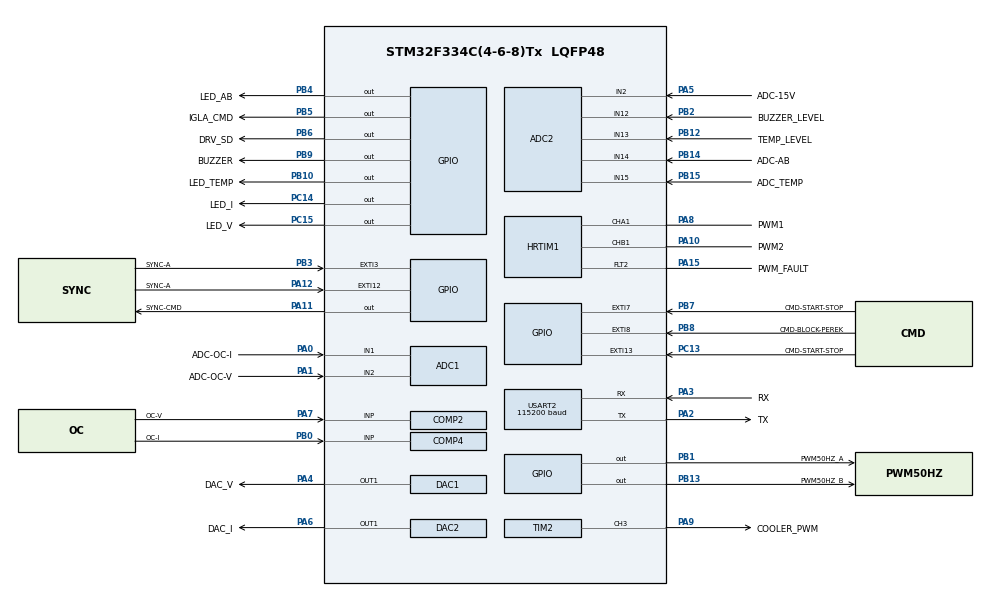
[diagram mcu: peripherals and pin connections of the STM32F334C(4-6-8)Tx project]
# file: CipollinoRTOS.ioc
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ADC1.ContinuousConvMode=ENABLE
ADC1.DMAContinuousRequests=ENABLE
ADC1.EnableRegularConversion=DISABLE
ADC1.ExternalTrigInjecConv=ADC_EXTERNALTRIGINJECCONV_HRTIM_TRG2
ADC1.ExternalTrigInjecConvEdge=ADC_EXTERNALTRIGINJECCONV_EDGE_RISINGFALLING
ADC1.InjNumberOfConversion=2
ADC1.InjectedChannel-1\#ChannelInjectedConversion=ADC_CHANNEL_1
ADC1.InjectedChannel-2\#ChannelInjectedConversion=ADC_CHANNEL_1
ADC1.InjectedConvMode=Discontinuous
ADC1.InjectedOffset-1\#ChannelInjectedConversion=0
ADC1.InjectedOffset-2\#ChannelInjectedConversion=0
ADC1.InjectedOffsetNumber-1\#ChannelInjectedConversion=ADC_OFFSET_NONE
ADC1.InjectedOffsetNumber-2\#ChannelInjectedConversion=ADC_OFFSET_NONE
ADC1.InjectedRank-1\#ChannelInjectedConversion=1
ADC1.InjectedRank-2\#ChannelInjectedConversion=2
ADC1.InjectedSamplingTime-1\#ChannelInjectedConversion=ADC_SAMPLETIME_7CYCLES_5
ADC1.InjectedSamplingTime-2\#ChannelInjectedConversion=ADC_SAMPLETIME_7CYCLES_5
ADC1.QueueInjectedContext=ENABLE
ADC1.SubFamily=STM32F334x8
ADC1.master=1
ADC2.AWD1HighThreshold=2500
ADC2.AWD1ITMode=DISABLE
ADC2.AWD1LowThreshold=1000
ADC2.Channel-0\#ChannelRegularConversion=ADC_CHANNEL_2
ADC2.Channel-2\#ChannelRegularConversion=ADC_CHANNEL_2
ADC2.Channel-3\#ChannelRegularConversion=ADC_CHANNEL_2
ADC2.Channel-4\#ChannelRegularConversion=ADC_CHANNEL_2
ADC2.Channel-5\#ChannelRegularConversion=ADC_CHANNEL_2
ADC2.ContinuousConvMode=ENABLE
ADC2.DMAContinuousRequests=ENABLE
ADC2.EOCSelection=ADC_EOC_SEQ_CONV
ADC2.EnableAnalogWatchDog1=true
ADC2.EnableAnalogWatchDog2=false
ADC2.EnableAnalogWatchDog3=false
ADC2.EnableInjectedConversion=DISABLE
ADC2.NbrOfConversion=5
ADC2.NbrOfConversionFlag=1
ADC2.Offset-0\#ChannelRegularConversion=0
ADC2.Offset-2\#ChannelRegularConversion=0
ADC2.Offset-3\#ChannelRegularConversion=0
ADC2.Offset-4\#ChannelRegularConversion=0
ADC2.Offset-5\#ChannelRegularConversion=0
ADC2.OffsetNumber-0\#ChannelRegularConversion=ADC_OFFSET_NONE
ADC2.OffsetNumber-2\#ChannelRegularConversion=ADC_OFFSET_NONE
ADC2.OffsetNumber-3\#ChannelRegularConversion=ADC_OFFSET_NONE
ADC2.OffsetNumber-4\#ChannelRegularConversion=ADC_OFFSET_NONE
ADC2.OffsetNumber-5\#ChannelRegularConversion=ADC_OFFSET_NONE
ADC2.Rank-0\#ChannelRegularConversion=1
ADC2.Rank-2\#ChannelRegularConversion=2
ADC2.Rank-3\#ChannelRegularConversion=3
ADC2.Rank-4\#ChannelRegularConversion=4
ADC2.Rank-5\#ChannelRegularConversion=5
ADC2.SamplingTime-0\#ChannelRegularConversion=ADC_SAMPLETIME_601CYCLES_5
ADC2.SamplingTime-2\#ChannelRegularConversion=ADC_SAMPLETIME_601CYCLES_5
ADC2.SamplingTime-3\#ChannelRegularConversion=ADC_SAMPLETIME_601CYCLES_5
ADC2.SamplingTime-4\#ChannelRegularConversion=ADC_SAMPLETIME_601CYCLES_5
ADC2.SamplingTime-5\#ChannelRegularConversion=ADC_SAMPLETIME_601CYCLES_5
ADC2.SubFamily=STM32F334x8
ADC2.WatchdogChannel=ADC_CHANNEL_2
COMP2.InvertingInput=COMP_INVERTINGINPUT_DAC1_CH1
COMP2.TriggerMode=COMP_TRIGGERMODE_IT_RISING_FALLING
COMP4.InvertingInput=COMP_INVERTINGINPUT_DAC2_CH1
COMP4.TriggerMode=COMP_TRIGGERMODE_IT_RISING_FALLING
Dma.ADC2.1.Direction=DMA_PERIPH_TO_MEMORY
Dma.ADC2.1.Instance=DMA1_Channel2
Dma.ADC2.1.MemDataAlignment=DMA_MDATAALIGN_HALFWORD
Dma.ADC2.1.MemInc=DMA_MINC_ENABLE
Dma.ADC2.1.Mode=DMA_CIRCULAR
Dma.ADC2.1.PeriphDataAlignment=DMA_PDATAALIGN_HALFWORD
Dma.ADC2.1.PeriphInc=DMA_PINC_DISABLE
Dma.ADC2.1.Priority=DMA_PRIORITY_MEDIUM
Dma.Request0=USART2_TX
Dma.Request1=ADC2
Dma.USART2_TX.0.Direction=DMA_MEMORY_TO_PERIPH
Dma.USART2_TX.0.Instance=DMA1_Channel7
Dma.USART2_TX.0.MemDataAlignment=DMA_MDATAALIGN_BYTE
Dma.USART2_TX.0.MemInc=DMA_MINC_ENABLE
Dma.USART2_TX.0.Mode=DMA_CIRCULAR
Dma.USART2_TX.0.PeriphDataAlignment=DMA_PDATAALIGN_BYTE
Dma.USART2_TX.0.PeriphInc=DMA_PINC_DISABLE
Dma.USART2_TX.0.Priority=DMA_PRIORITY_LOW
HRTIM1.ADCTrigger1_Source1=HRTIM_ADCTRIGGEREVENT13_MASTER_CMP1
HRTIM1.ADCTrigger1_Source2=HRTIM_ADCTRIGGEREVENT13_MASTER_CMP2
HRTIM1.ADCTrigger1_Source3=HRTIM_ADCTRIGGEREVENT13_MASTER_CMP3
HRTIM1.ADCTrigger1_Source4=HRTIM_ADCTRIGGEREVENT13_MASTER_CMP4
HRTIM1.ADCTrigger2_Source1=HRTIM_ADCTRIGGEREVENT24_MASTER_CMP1
HRTIM1.ADCTrigger2_Source2=HRTIM_ADCTRIGGEREVENT24_MASTER_CMP3
HRTIM1.ADCTrigger2_Source3=HRTIM_ADCTRIGGEREVENT24_TIMERA_CMP2
HRTIM1.ADCTrigger2_Source4=HRTIM_ADCTRIGGEREVENT24_TIMERA_CMP3
HRTIM1.ADCTrigger2_Source5=HRTIM_ADCTRIGGEREVENT24_TIMERA_CMP4
HRTIM1.ADCTrigger2_Source6=HRTIM_ADCTRIGGEREVENT24_TIMERB_CMP2
HRTIM1.ADCTrigger2_Source7=HRTIM_ADCTRIGGEREVENT24_TIMERB_CMP3
HRTIM1.ADCTrigger2_Source8=HRTIM_ADCTRIGGEREVENT24_TIMERB_CMP4
HRTIM1.ADCTrigger3_Source1=HRTIM_ADCTRIGGEREVENT13_TIMERB_CMP2
HRTIM1.ADCTrigger3_Source2=HRTIM_ADCTRIGGEREVENT13_TIMERB_CMP3
HRTIM1.ADCTrigger3_Source3=HRTIM_ADCTRIGGEREVENT13_TIMERB_CMP4
HRTIM1.ADCTrigger4_Source1=HRTIM_ADCTRIGGEREVENT24_MASTER_PERIOD
HRTIM1.ADCTrigger_Id1=__NULL
HRTIM1.ADCTrigger_Id2=HRTIM_ADCTRIGGER_2
HRTIM1.ADCTrigger_Id3=__NULL
HRTIM1.ADCTrigger_Id4=__NULL
HRTIM1.CaptureUnit1-Output_TA1=HRTIM_CAPTUREUNIT_1
HRTIM1.CaptureUnit1-Output_TB1=HRTIM_CAPTUREUNIT_1
HRTIM1.CaptureUnit2-Output_TA1=HRTIM_CAPTUREUNIT_2
HRTIM1.CaptureUnit2-Output_TB1=HRTIM_CAPTUREUNIT_2
HRTIM1.CompareUnit1-MasterTimer=HRTIM_COMPAREUNIT_1
HRTIM1.CompareUnit1-Output_TA1=HRTIM_COMPAREUNIT_1
HRTIM1.CompareUnit1-Output_TB1=HRTIM_COMPAREUNIT_1
HRTIM1.CompareUnit2-MasterTimer=HRTIM_COMPAREUNIT_2
HRTIM1.CompareUnit2-Output_TA1=HRTIM_COMPAREUNIT_2
HRTIM1.CompareUnit2-Output_TB1=HRTIM_COMPAREUNIT_2
HRTIM1.CompareUnit3-MasterTimer=HRTIM_COMPAREUNIT_3
HRTIM1.CompareUnit3-Output_TA1=HRTIM_COMPAREUNIT_3
HRTIM1.CompareUnit3-Output_TB1=HRTIM_COMPAREUNIT_3
HRTIM1.CompareUnit4-MasterTimer=HRTIM_COMPAREUNIT_4
HRTIM1.CompareUnit4-Output_TA1=HRTIM_COMPAREUNIT_4
HRTIM1.CompareUnit4-Output_TB1=HRTIM_COMPAREUNIT_4
HRTIM1.CompareValue1-MasterTimer=2300
HRTIM1.CompareValue1-Output_TA1=7000
HRTIM1.CompareValue1-Output_TB1=40000
HRTIM1.CompareValue2-MasterTimer=30459
HRTIM1.CompareValue2-Output_TA1=14000
HRTIM1.CompareValue2-Output_TB1=47000
HRTIM1.CompareValue3-MasterTimer=35059
HRTIM1.CompareValue3-Output_TA1=21000
HRTIM1.CompareValue3-Output_TB1=54000
HRTIM1.CompareValue4-MasterTimer=63219
HRTIM1.CompareValue4-Output_TA1=28000
HRTIM1.CompareValue4-Output_TB1=61000
HRTIM1.EnableCalibration=DLLSimpleCalibration
HRTIM1.Event4-Output_TA1=__NULL
HRTIM1.Event_EEV1=HRTIM_EVENT_1
HRTIM1.Event_EEV2=HRTIM_EVENT_2
HRTIM1.Event_EEV3=__NULL
HRTIM1.Event_EEV4=HRTIM_EVENT_4
HRTIM1.FastMode_EEV1=HRTIM_EVENTFASTMODE_ENABLE
HRTIM1.FastMode_EEV2=HRTIM_EVENTFASTMODE_ENABLE
HRTIM1.FastMode_EEV4=HRTIM_EVENTFASTMODE_ENABLE
HRTIM1.FaultEnable_Source1-Output_TA1=HRTIM_TIMFAULTENABLE_FAULT2
HRTIM1.FaultEnable_Source1-Output_TB1=HRTIM_TIMFAULTENABLE_FAULT2
HRTIM1.FaultLevel1-Output_TA1=HRTIM_OUTPUTFAULTLEVEL_INACTIVE
HRTIM1.FaultLevel1-Output_TB1=HRTIM_OUTPUTFAULTLEVEL_INACTIVE
HRTIM1.Filter_FaultLine2=HRTIM_FAULTFILTER_15
HRTIM1.HRTIMInterruptResquests1=HRTIM_IT_FLT2
HRTIM1.HRTIMInterruptResquests2=HRTIM_IT_SYSFLT
HRTIM1.InterruptRequests1-Output_TA1=HRTIM_TIM_IT_CMP1
HRTIM1.InterruptRequests1-Output_TB1=HRTIM_TIM_IT_CMP1
HRTIM1.InterruptRequests1_Master=HRTIM_MASTER_IT_MREP
HRTIM1.InterruptRequests2-Output_TA1=HRTIM_TIM_IT_CMP2
HRTIM1.InterruptRequests2-Output_TB1=HRTIM_TIM_IT_CMP2
HRTIM1.InterruptRequests2_Master=HRTIM_MASTER_IT_MCMP1
HRTIM1.InterruptRequests3-Output_TA1=HRTIM_TIM_IT_CMP3
HRTIM1.InterruptRequests3-Output_TB1=HRTIM_TIM_IT_CMP3
HRTIM1.InterruptRequests3_Master=HRTIM_MASTER_IT_MCMP2
HRTIM1.InterruptRequests4-Output_TA1=HRTIM_TIM_IT_CMP4
HRTIM1.InterruptRequests4-Output_TB1=HRTIM_TIM_IT_CMP4
HRTIM1.InterruptRequests4_Master=HRTIM_MASTER_IT_MCMP3
HRTIM1.InterruptRequests5-Output_TA1=HRTIM_TIM_IT_CPT1
HRTIM1.InterruptRequests5-Output_TB1=HRTIM_TIM_IT_CPT1
HRTIM1.InterruptRequests5_Master=HRTIM_MASTER_IT_MCMP4
HRTIM1.InterruptRequests6-Output_TA1=HRTIM_TIM_IT_CPT2
HRTIM1.InterruptRequests6-Output_TB1=HRTIM_TIM_IT_CPT2
HRTIM1.ModeTimeBase-Output_TA1=HRTIM_MODE_SINGLESHOT_RETRIGGERABLE
HRTIM1.ModeTimeBase-Output_TB1=HRTIM_MODE_SINGLESHOT_RETRIGGERABLE
HRTIM1.NumberADCTriggerSource1=4
HRTIM1.NumberADCTriggerSource2=8
HRTIM1.NumberADCTriggerSource3=3
HRTIM1.NumberADCTriggerSource4=1
HRTIM1.NumberDMARequests_Master=0
HRTIM1.NumberFaultEnable-Output_TA1=1
HRTIM1.NumberFaultEnable-Output_TB1=1
HRTIM1.NumberInterruptRequests-Output_TA1=6
HRTIM1.NumberInterruptRequests-Output_TB1=6
HRTIM1.NumberInterruptRequests_Master-MasterTimer=5
HRTIM1.NumberResetSource1-Output_TA1=4
HRTIM1.NumberResetSource1-Output_TB1=4
HRTIM1.NumberResetTrigger-Output_TA1=4
HRTIM1.NumberResetTrigger-Output_TB1=4
HRTIM1.NumberSetSource1-Output_TA1=1
HRTIM1.NumberSetSource1-Output_TB1=1
HRTIM1.NumberTriggerSource_Captureconfig1-Output_TA1=2
HRTIM1.NumberTriggerSource_Captureconfig1-Output_TB1=2
HRTIM1.NumberTriggerSource_Captureconfig2-Output_TA1=1
HRTIM1.NumberTriggerSource_Captureconfig2-Output_TB1=1
HRTIM1.NumberUpdateTrigger-Output_TA1=1
HRTIM1.NumberUpdateTrigger-Output_TB1=1
HRTIM1.ORingUpdateSource_ADCTrigger1=HRTIM_ADCTRIGGERUPDATE_MASTER
HRTIM1.ORingUpdateSource_ADCTrigger2=HRTIM_ADCTRIGGERUPDATE_MASTER
HRTIM1.ORingUpdateSource_ADCTrigger3=HRTIM_ADCTRIGGERUPDATE_TIMER_B
HRTIM1.Periode_MASTER=65503
HRTIM1.PrescalerRatio_MASTER=HRTIM_PRESCALERRATIO_MUL16
HRTIM1.PrescalerRatio_TA=HRTIM_PRESCALERRATIO_MUL16
HRTIM1.PrescalerRatio_TB=HRTIM_PRESCALERRATIO_MUL16
HRTIM1.ResetOutput1_Source1-Output_TA1=HRTIM_OUTPUTRESET_MASTERCMP2
HRTIM1.ResetOutput1_Source1-Output_TB1=HRTIM_OUTPUTRESET_MASTERCMP4
HRTIM1.ResetOutput1_Source2-Output_TA1=HRTIM_OUTPUTRESET_EEV_1
HRTIM1.ResetOutput1_Source2-Output_TB1=HRTIM_OUTPUTRESET_EEV_1
HRTIM1.ResetOutput1_Source3-Output_TA1=HRTIM_OUTPUTRESET_EEV_2
HRTIM1.ResetOutput1_Source3-Output_TB1=HRTIM_OUTPUTRESET_EEV_2
HRTIM1.ResetOutput1_Source4-Output_TA1=HRTIM_OUTPUTRESET_EEV_4
HRTIM1.ResetOutput1_Source4-Output_TB1=HRTIM_OUTPUTRESET_EEV_4
HRTIM1.ResetTrigger1-Output_TA1=HRTIM_TIMRESETTRIGGER_MASTER_CMP2
HRTIM1.ResetTrigger1-Output_TB1=HRTIM_TIMRESETTRIGGER_MASTER_CMP4
HRTIM1.ResetTrigger2-Output_TA1=HRTIM_TIMRESETTRIGGER_EEV_1
HRTIM1.ResetTrigger2-Output_TB1=HRTIM_TIMRESETTRIGGER_EEV_1
HRTIM1.ResetTrigger3-Output_TA1=HRTIM_TIMRESETTRIGGER_EEV_2
HRTIM1.ResetTrigger3-Output_TB1=HRTIM_TIMRESETTRIGGER_EEV_2
HRTIM1.ResetTrigger4-Output_TA1=HRTIM_TIMRESETTRIGGER_EEV_4
HRTIM1.ResetTrigger4-Output_TB1=HRTIM_TIMRESETTRIGGER_EEV_4
HRTIM1.Sensitivity_EEV1=HRTIM_EVENTSENSITIVITY_LEVEL
HRTIM1.SetOutput1_Source1-Output_TA1=HRTIM_OUTPUTSET_MASTERCMP1
HRTIM1.SetOutput1_Source1-Output_TB1=HRTIM_OUTPUTSET_MASTERCMP3
HRTIM1.Source_EEV4=HRTIM_EVENTSRC_4
HRTIM1.TriggerCapture1_Source1-Output_TA1=HRTIM_CAPTURETRIGGER_EEV_1
HRTIM1.TriggerCapture1_Source1-Output_TB1=HRTIM_CAPTURETRIGGER_EEV_1
HRTIM1.TriggerCapture1_Source2-Output_TA1=HRTIM_CAPTURETRIGGER_EEV_2
HRTIM1.TriggerCapture1_Source2-Output_TB1=HRTIM_CAPTURETRIGGER_EEV_2
HRTIM1.TriggerCapture2_Source1-Output_TA1=HRTIM_CAPTURETRIGGER_TA1_RESET
HRTIM1.TriggerCapture2_Source1-Output_TB1=HRTIM_CAPTURETRIGGER_TB1_SET
HRTIM1.UpdateTrigger1-Output_TA1=HRTIM_TIMUPDATETRIGGER_MASTER
HRTIM1.UpdateTrigger1-Output_TB1=HRTIM_TIMUPDATETRIGGER_MASTER
IWDG.Prescaler=IWDG_PRESCALER_128
Mcu.Family=STM32F3
Mcu.Name=STM32F334C(4-6-8)Tx
Mcu.Package=LQFP48
NVIC.COMP2_IRQn=true\:0\:0\:false\:false\:true\:false\:true
NVIC.COMP4_6_IRQn=true\:0\:0\:false\:false\:true\:false\:true
NVIC.DMA1_Channel2_IRQn=true\:0\:0\:false\:false\:true\:false\:true
NVIC.DMA1_Channel7_IRQn=true\:0\:0\:false\:false\:true\:false\:true
NVIC.EXTI15_10_IRQn=true\:0\:2\:false\:false\:true\:true\:true
NVIC.EXTI3_IRQn=true\:0\:2\:false\:false\:true\:true\:true
NVIC.EXTI9_5_IRQn=true\:0\:2\:false\:false\:true\:true\:true
NVIC.HRTIM1_FLT_IRQn=true\:0\:0\:false\:false\:true\:true\:true
NVIC.HRTIM1_Master_IRQn=true\:0\:0\:false\:false\:true\:true\:true
NVIC.HRTIM1_TIMA_IRQn=true\:0\:0\:false\:false\:true\:true\:true
NVIC.HRTIM1_TIMB_IRQn=true\:0\:0\:false\:false\:true\:true\:true
NVIC.PVD_IRQn=true\:0\:2\:true\:false\:true\:true\:true
NVIC.PriorityGroup=NVIC_PRIORITYGROUP_1
PA0.GPIO_Label=ADC-OC-I
PA0.Mode=IN1-Single-Ended
PA0.Signal=ADC1_IN1
PA1.GPIO_Label=ADC-OC-V
PA1.Mode=IN2-Single-Ended
PA1.Signal=ADC1_IN2
PA10.GPIO_Label=PWM2
PA10.Mode=Output_TB1
PA10.Signal=HRTIM1_CHB1
PA11.GPIO_Label=SYNC-CMD
PA11.GPIO_Speed=GPIO_SPEED_FREQ_HIGH
PA11.Signal=GPIO_Output
PA12.GPIO_Label=SYNC-A
PA12.GPIO_ModeDefaultEXTI=GPIO_MODE_IT_RISING_FALLING
PA12.Signal=GPXTI12
PA13.GPIO_Label=DIO
PA13.Mode=Serial_Wire
PA13.Signal=SYS_JTMS-SWDIO
PA14.GPIO_Label=CLK
PA14.Mode=Serial_Wire
PA14.Signal=SYS_JTCK-SWCLK
PA15.GPIO_Label=PWM_FAULT
PA15.Mode=Fault_Enable2
PA15.Signal=HRTIM1_FLT2
PA2.GPIO_Label=TX
PA2.Mode=Asynchronous
PA2.Signal=USART2_TX
PA3.GPIO_Label=RX
PA3.Mode=Asynchronous
PA3.Signal=USART2_RX
PA4.GPIO_Label=DAC_V
PA4.Signal=COMP_DAC11_group
PA5.GPIO_Label=ADC-15V
PA5.Mode=IN2-Single-Ended
PA5.Signal=ADC2_IN2
PA6.GPIO_Label=DAC_I
PA6.Signal=COMP_DAC21_group
PA7.GPIO_Label=OC-V
PA7.Mode=INP
PA7.Signal=COMP2_INP
PA8.GPIO_Label=PWM1
PA8.Mode=Output_TA1
PA8.Signal=HRTIM1_CHA1
PA9.GPIO_Label=COOLER_PWM
PA9.GPIO_Speed=GPIO_SPEED_FREQ_HIGH
PA9.Signal=S_TIM2_CH3
PB0.GPIO_Label=OC-I
PB0.Mode=INP
PB0.Signal=COMP4_INP
PB1.GPIO_Label=PWM50HZ_A
PB1.GPIO_Speed=GPIO_SPEED_FREQ_HIGH
PB1.Signal=GPIO_Output
PB10.GPIO_Label=LED_TEMP
PB10.GPIO_Speed=GPIO_SPEED_FREQ_HIGH
PB10.Signal=GPIO_Output
PB12.GPIO_Label=TEMP_LEVEL
PB12.Mode=IN13-Single-Ended
PB12.Signal=ADC2_IN13
PB13.GPIO_Label=PWM50HZ_B
PB13.GPIO_Speed=GPIO_SPEED_FREQ_HIGH
PB13.Signal=GPIO_Output
PB14.GPIO_Label=ADC-AB
PB14.Mode=IN14-Single-Ended
PB14.Signal=ADC2_IN14
PB15.GPIO_Label=ADC_TEMP
PB15.Mode=IN15-Single-Ended
PB15.Signal=ADC2_IN15
PB2.GPIO_Label=BUZZER_LEVEL
PB2.Mode=IN12-Single-Ended
PB2.Signal=ADC2_IN12
PB3.GPIO_Label=SYNC-A
PB3.GPIO_ModeDefaultEXTI=GPIO_MODE_IT_RISING_FALLING
PB3.Signal=GPXTI3
PB4.GPIO_Label=LED_AB
PB4.GPIO_Speed=GPIO_SPEED_FREQ_HIGH
PB4.Signal=GPIO_Output
PB5.GPIO_Label=IGLA_CMD
PB5.GPIO_Speed=GPIO_SPEED_FREQ_HIGH
PB5.Signal=GPIO_Output
PB6.GPIO_FM6=SYSCFG_CFGR1_I2C_PB6_FMP
PB6.GPIO_Label=DRV_SD
PB6.GPIO_Speed=GPIO_SPEED_FREQ_HIGH
PB6.Signal=GPIO_Output
PB7.GPIO_Label=CMD-START-STOP
PB7.GPIO_ModeDefaultEXTI=GPIO_MODE_IT_RISING_FALLING
PB7.Signal=GPXTI7
PB8.GPIO_Label=CMD-BLOCK-PEREK
PB8.GPIO_ModeDefaultEXTI=GPIO_MODE_IT_RISING_FALLING
PB8.Signal=GPXTI8
PB9.GPIO_FM9=SYSCFG_CFGR1_I2C_PB9_FMP
PB9.GPIO_Label=BUZZER
PB9.GPIO_Speed=GPIO_SPEED_FREQ_HIGH
PB9.Signal=GPIO_Output
PC13.GPIO_Label=CMD-START-STOP
PC13.GPIO_ModeDefaultEXTI=GPIO_MODE_IT_RISING_FALLING
PC13.Signal=GPXTI13
PC14\ /\ OSC32_IN.GPIO_Label=LED_I
PC14\ /\ OSC32_IN.GPIO_Speed=GPIO_SPEED_FREQ_HIGH
PC14\ /\ OSC32_IN.Signal=GPIO_Output
PC15\ /\ OSC32_OUT.GPIO_Label=LED_V
PC15\ /\ OSC32_OUT.GPIO_Speed=GPIO_SPEED_FREQ_HIGH
PC15\ /\ OSC32_OUT.Signal=GPIO_Output
PF0\ /\ OSC_IN.GPIO_Label=OSC_IN
PF0\ /\ OSC_IN.Mode=HSE-External-Oscillator
PF0\ /\ OSC_IN.Signal=RCC_OSC_IN
PF1\ /\ OSC_OUT.GPIO_Label=OSC_OUT
PF1\ /\ OSC_OUT.Mode=HSE-External-Oscillator
PF1\ /\ OSC_OUT.Signal=RCC_OSC_OUT
ProjectManager.HeapSize=0x200
ProjectManager.StackSize=0x400
ProjectManager.TargetToolchain=STM32CubeIDE
RCC.AHBFreq_Value=72000000
RCC.APB1CLKDivider=RCC_HCLK_DIV2
RCC.APB1Freq_Value=36000000
RCC.APB1TimFreq_Value=72000000
RCC.APB2Freq_Value=72000000
RCC.APB2TimFreq_Value=72000000
RCC.CortexFreq_Value=72000000
RCC.HCLKFreq_Value=72000000
RCC.HRTIMSelection=RCC_HRTIM1CLK_PLLCLK
RCC.HSE_VALUE=12000000
RCC.HSI_VALUE=8000000
RCC.LSE_VALUE=32768
RCC.PLLMUL=RCC_PLL_MUL6
RCC.PLLSourceVirtual=RCC_PLLSOURCE_HSE
RCC.SYSCLKFreq_VALUE=72000000
RCC.SYSCLKSourceVirtual=RCC_SYSCLKSOURCE_PLLCLK
SH.COMP_DAC11_group.0=DAC1_OUT1,DAC_OUT1
SH.COMP_DAC21_group.0=DAC2_OUT1,Switch_Enable_OUT1
SH.S_TIM2_CH3.0=TIM2_CH3,PWM Generation3 CH3
TIM2.AutoReloadPreload=TIM_AUTORELOAD_PRELOAD_ENABLE
TIM2.Channel-PWM\ Generation3\ CH3=TIM_CHANNEL_3
TIM2.OCFastMode_PWM-PWM\ Generation3\ CH3=TIM_OCFAST_ENABLE
TIM2.Period=35999
TIM2.Prescaler=1
USART2.BaudRate=115200
USART2.VirtualMode-Asynchronous=VM_ASYNC
VP_COMP2_VS_DAC1OUT1.Mode=INM_DAC1OUT1
VP_COMP4_VS_DAC2OUT1.Mode=INM_DAC2OUT1
VP_CRC_VS_CRC.Mode=CRC_Activate
VP_HRTIM1_VS_hrtimMasterTimerNoOutput.Mode=MasterTimer
VP_IWDG_VS_IWDG.Mode=IWDG_Activate
board=custom

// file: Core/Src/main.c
/* USER CODE BEGIN Header */
/**
  ******************************************************************************
  * @file           : main.c
  * @brief          : Main program body
  ******************************************************************************
  * @attention
  *
  * <h2><center>&copy; Copyright (c) 2020 STMicroelectronics.
  * All rights reserved.</center></h2>
  *
  * This software component is licensed by ST under BSD 3-Clause license,
  * the "License"; You may not use this file except in compliance with the
  * License. You may obtain a copy of the License at:
  *                        opensource.org/licenses/BSD-3-Clause
  *
  ******************************************************************************
  */
/* USER CODE END Header */

#include "main.h"
#include "adc.h"
#include "comp.h"
#include "crc.h"
#include "dac.h"
#include "dma.h"
#include "hrtim.h"
#include "iwdg.h"
#include "tim.h"
#include "usart.h"
#include "gpio.h"

void SystemClock_Config(void);

int main(void)
{
  /* USER CODE BEGIN 1 */
	Enable_SH_DEBUG();
  /* USER CODE END 1 */

  /* MCU Configuration--------------------------------------------------------*/

  /* Reset of all peripherals, Initializes the Flash interface and the Systick. */

  LL_APB2_GRP1_EnableClock(LL_APB2_GRP1_PERIPH_SYSCFG);
  LL_APB1_GRP1_EnableClock(LL_APB1_GRP1_PERIPH_PWR);

  NVIC_SetPriorityGrouping(NVIC_PRIORITYGROUP_1);

  /* System interrupt init*/
  /* SysTick_IRQn interrupt configuration */
  NVIC_SetPriority(SysTick_IRQn, NVIC_EncodePriority(NVIC_GetPriorityGrouping(),0, 1));

  /* Peripheral interrupt init*/
  /* PVD_IRQn interrupt configuration */
  NVIC_SetPriority(PVD_IRQn, NVIC_EncodePriority(NVIC_GetPriorityGrouping(),0, 2));
  NVIC_EnableIRQ(PVD_IRQn);

  /* Configure the system clock */
  SystemClock_Config();

  /* USER CODE BEGIN SysInit */
  LL_SYSTICK_EnableIT(); // Enable SysTick Interrupt
  /* USER CODE END SysInit */

  /* Initialize all configured peripherals */
  MX_GPIO_Init();
  MX_DMA_Init();
  MX_IWDG_Init();
  MX_CRC_Init();
  MX_HRTIM1_Init();
  MX_USART2_UART_Init();
  MX_ADC1_Init();
  MX_ADC2_Init();
  MX_COMP2_Init();
  MX_COMP4_Init();
  MX_DAC1_Init();
  MX_DAC2_Init();
  MX_TIM2_Init();
  /* USER CODE BEGIN 2 */
  SetupQuarkTS();
  RunQuarkTS();
  /* USER CODE END 2 */

  /* Infinite loop */
  while (1)
  {

  }
}

void SystemClock_Config(void)
{
  LL_FLASH_SetLatency(LL_FLASH_LATENCY_2);

   if(LL_FLASH_GetLatency() != LL_FLASH_LATENCY_2)
  {
  Error_Handler();
  }
  LL_RCC_HSE_Enable();

   /* Wait till HSE is ready */
  while(LL_RCC_HSE_IsReady() != 1)
  {

  }
  LL_RCC_LSI_Enable();

   /* Wait till LSI is ready */
  while(LL_RCC_LSI_IsReady() != 1)
  {

  }
  LL_RCC_PLL_ConfigDomain_SYS(LL_RCC_PLLSOURCE_HSE_DIV_1, LL_RCC_PLL_MUL_6);
  LL_RCC_PLL_Enable();

   /* Wait till PLL is ready */
  while(LL_RCC_PLL_IsReady() != 1)
  {

  }
  LL_RCC_SetAHBPrescaler(LL_RCC_SYSCLK_DIV_1);
  LL_RCC_SetAPB1Prescaler(LL_RCC_APB1_DIV_2);
  LL_RCC_SetAPB2Prescaler(LL_RCC_APB1_DIV_1);
  LL_RCC_SetSysClkSource(LL_RCC_SYS_CLKSOURCE_PLL);

   /* Wait till System clock is ready */
  while(LL_RCC_GetSysClkSource() != LL_RCC_SYS_CLKSOURCE_STATUS_PLL)
  {

  }

  LL_Init1msTick(72000000);
  LL_SYSTICK_SetClkSource(LL_SYSTICK_CLKSOURCE_HCLK);
  LL_SetSystemCoreClock(72000000);
  LL_RCC_SetHRTIMClockSource(RCC_CFGR3_HRTIM1SW_PLL);
  LL_RCC_SetADCClockSource(LL_RCC_ADC12_CLKSRC_PLL_DIV_1);
}

void Error_Handler(void)
{
}

/************************ (C) COPYRIGHT STMicroelectronics *****END OF FILE****/
